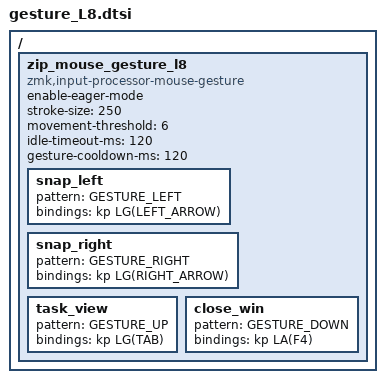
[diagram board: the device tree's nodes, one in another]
#include <dt-bindings/zmk/keys.h>

 / {
  zip_mouse_gesture_l8: zip_mouse_gesture_l8 {
    compatible = "zmk,input-processor-mouse-gesture";
    #input-processor-cells = <0>;

    enable-eager-mode;
    stroke-size = <250>;
    movement-threshold = <6>;
    idle-timeout-ms = <120>;
    gesture-cooldown-ms = <120>;

    snap_left   { pattern = <GESTURE_LEFT>;  bindings = <&kp LG(LEFT_ARROW)>; };
    snap_right  { pattern = <GESTURE_RIGHT>; bindings = <&kp LG(RIGHT_ARROW)>; };
    task_view   { pattern = <GESTURE_UP>;    bindings = <&kp LG(TAB)>; };
    close_win   { pattern = <GESTURE_DOWN>;  bindings = <&kp LA(F4)>; };
  };
};
